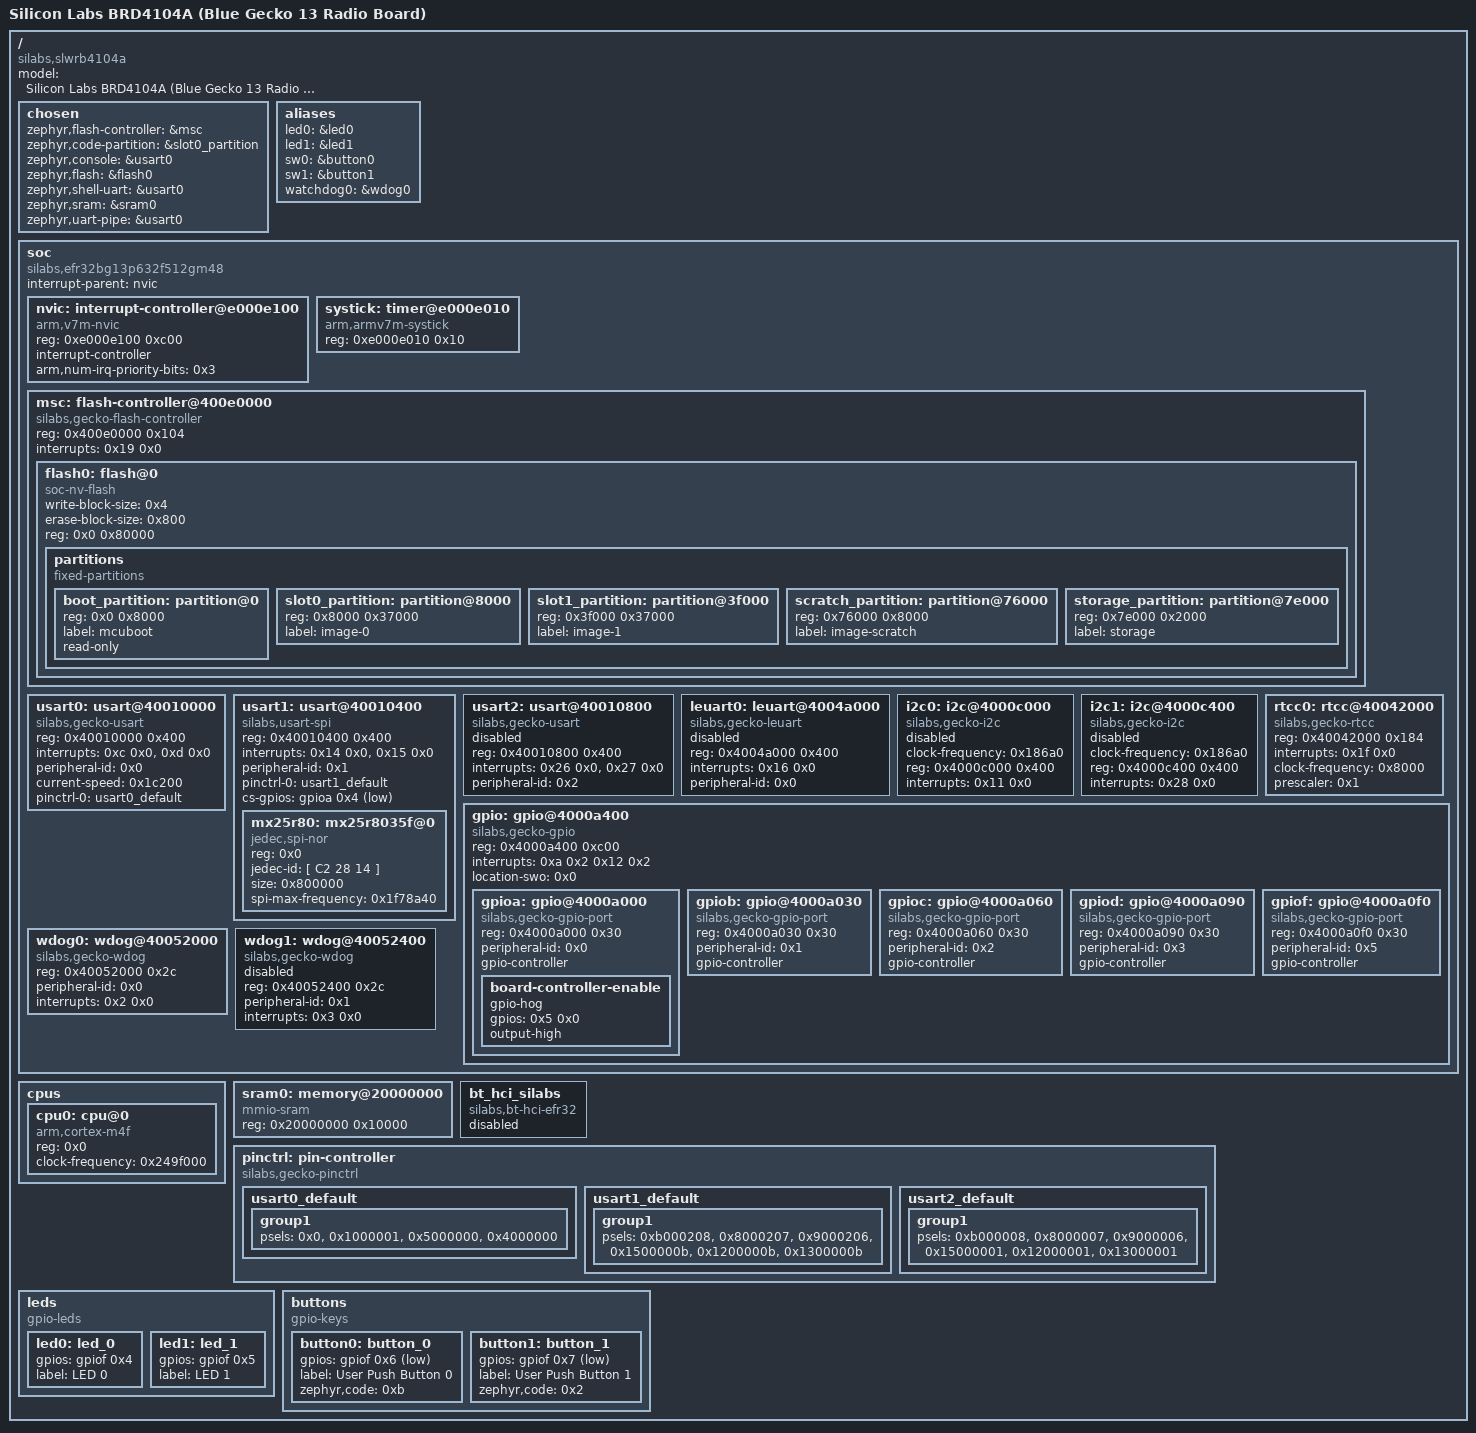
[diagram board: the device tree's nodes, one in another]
/dts-v1/;

/* node '/' defined in zephyr/dts/common/skeleton.dtsi:9 */
/ {
	#address-cells = < 0x1 >;                                    /* in zephyr/dts/common/skeleton.dtsi:10 */
	#size-cells = < 0x1 >;                                       /* in zephyr/dts/common/skeleton.dtsi:11 */
	model = "Silicon Labs BRD4104A (Blue Gecko 13 Radio Board)"; /* in zephyr/boards/silabs/radio_boards/slwrb4104a/slwrb4104a.dts:12 */
	compatible = "silabs,slwrb4104a",
	             "silabs,efr32bg13p";                            /* in zephyr/boards/silabs/radio_boards/slwrb4104a/slwrb4104a.dts:13 */

	/* node '/chosen' defined in zephyr/dts/common/skeleton.dtsi:13 */
	chosen {
		zephyr,flash-controller = &msc;           /* in zephyr/dts/arm/silabs/xg13/efr32xg13.dtsi:13 */
		zephyr,code-partition = &slot0_partition; /* in zephyr/boards/silabs/radio_boards/common/efr32-series1-common.dtsi:12 */
		zephyr,console = &usart0;                 /* in zephyr/boards/silabs/radio_boards/common/efr32-series1-common.dtsi:13 */
		zephyr,flash = &flash0;                   /* in zephyr/boards/silabs/radio_boards/common/efr32-series1-common.dtsi:14 */
		zephyr,shell-uart = &usart0;              /* in zephyr/boards/silabs/radio_boards/common/efr32-series1-common.dtsi:15 */
		zephyr,sram = &sram0;                     /* in zephyr/boards/silabs/radio_boards/common/efr32-series1-common.dtsi:16 */
		zephyr,uart-pipe = &usart0;               /* in zephyr/boards/silabs/radio_boards/common/efr32-series1-common.dtsi:17 */
	};

	/* node '/aliases' defined in zephyr/dts/common/skeleton.dtsi:15 */
	aliases {
		led0 = &led0;       /* in zephyr/boards/silabs/radio_boards/common/efr32-series1-common.dtsi:22 */
		led1 = &led1;       /* in zephyr/boards/silabs/radio_boards/common/efr32-series1-common.dtsi:23 */
		sw0 = &button0;     /* in zephyr/boards/silabs/radio_boards/common/efr32-series1-common.dtsi:24 */
		sw1 = &button1;     /* in zephyr/boards/silabs/radio_boards/common/efr32-series1-common.dtsi:25 */
		watchdog0 = &wdog0; /* in zephyr/boards/silabs/radio_boards/common/efr32-series1-common.dtsi:26 */
	};

	/* node '/soc' defined in zephyr/dts/arm/armv7-m.dtsi:6 */
	soc {
		#address-cells = < 0x1 >;                    /* in zephyr/dts/arm/armv7-m.dtsi:7 */
		#size-cells = < 0x1 >;                       /* in zephyr/dts/arm/armv7-m.dtsi:8 */
		interrupt-parent = < &nvic >;                /* in zephyr/dts/arm/armv7-m.dtsi:10 */
		ranges;                                      /* in zephyr/dts/arm/armv7-m.dtsi:11 */
		compatible = "silabs,efr32bg13p632f512gm48",
		             "silabs,efr32xg13p",
		             "silabs,efr32",
		             "simple-bus";                   /* in zephyr/dts/arm/silabs/xg13/efr32bg13p632f512gm48.dtsi:12 */

		/* node '/soc/interrupt-controller@e000e100' defined in zephyr/dts/arm/armv7-m.dtsi:13 */
		nvic: interrupt-controller@e000e100 {
			#address-cells = < 0x1 >;            /* in zephyr/dts/arm/armv7-m.dtsi:14 */
			compatible = "arm,v7m-nvic";         /* in zephyr/dts/arm/armv7-m.dtsi:15 */
			reg = < 0xe000e100 0xc00 >;          /* in zephyr/dts/arm/armv7-m.dtsi:16 */
			interrupt-controller;                /* in zephyr/dts/arm/armv7-m.dtsi:17 */
			#interrupt-cells = < 0x2 >;          /* in zephyr/dts/arm/armv7-m.dtsi:18 */
			arm,num-irq-priority-bits = < 0x3 >; /* in zephyr/dts/arm/silabs/xg13/efr32xg13.dtsi:198 */
			phandle = < 0x1 >;                   /* in zephyr/dts/arm/armv7-m.dtsi:10 */
		};

		/* node '/soc/timer@e000e010' defined in zephyr/dts/arm/armv7-m.dtsi:21 */
		systick: timer@e000e010 {
			compatible = "arm,armv7m-systick"; /* in zephyr/dts/arm/armv7-m.dtsi:22 */
			reg = < 0xe000e010 0x10 >;         /* in zephyr/dts/arm/armv7-m.dtsi:23 */
		};

		/* node '/soc/flash-controller@400e0000' defined in zephyr/dts/arm/silabs/xg13/efr32xg13.dtsi:31 */
		msc: flash-controller@400e0000 {
			compatible = "silabs,gecko-flash-controller"; /* in zephyr/dts/arm/silabs/xg13/efr32xg13.dtsi:32 */
			reg = < 0x400e0000 0x104 >;                   /* in zephyr/dts/arm/silabs/xg13/efr32xg13.dtsi:33 */
			interrupts = < 0x19 0x0 >;                    /* in zephyr/dts/arm/silabs/xg13/efr32xg13.dtsi:34 */
			#address-cells = < 0x1 >;                     /* in zephyr/dts/arm/silabs/xg13/efr32xg13.dtsi:36 */
			#size-cells = < 0x1 >;                        /* in zephyr/dts/arm/silabs/xg13/efr32xg13.dtsi:37 */

			/* node '/soc/flash-controller@400e0000/flash@0' defined in zephyr/dts/arm/silabs/xg13/efr32xg13.dtsi:39 */
			flash0: flash@0 {
				compatible = "soc-nv-flash";  /* in zephyr/dts/arm/silabs/xg13/efr32xg13.dtsi:40 */
				write-block-size = < 0x4 >;   /* in zephyr/dts/arm/silabs/xg13/efr32xg13.dtsi:41 */
				erase-block-size = < 0x800 >; /* in zephyr/dts/arm/silabs/xg13/efr32xg13.dtsi:42 */
				reg = < 0x0 0x80000 >;        /* in zephyr/dts/arm/silabs/xg13/efr32bg13p632f512gm48.dtsi:18 */

				/* node '/soc/flash-controller@400e0000/flash@0/partitions' defined in zephyr/boards/silabs/radio_boards/slwrb4104a/slwrb4104a.dts:21 */
				partitions {
					compatible = "fixed-partitions"; /* in zephyr/boards/silabs/radio_boards/slwrb4104a/slwrb4104a.dts:22 */
					#address-cells = < 0x1 >;        /* in zephyr/boards/silabs/radio_boards/slwrb4104a/slwrb4104a.dts:23 */
					#size-cells = < 0x1 >;           /* in zephyr/boards/silabs/radio_boards/slwrb4104a/slwrb4104a.dts:24 */

					/* node '/soc/flash-controller@400e0000/flash@0/partitions/partition@0' defined in zephyr/boards/silabs/radio_boards/slwrb4104a/slwrb4104a.dts:27 */
					boot_partition: partition@0 {
						reg = < 0x0 0x8000 >; /* in zephyr/boards/silabs/radio_boards/slwrb4104a/slwrb4104a.dts:28 */
						label = "mcuboot";    /* in zephyr/boards/silabs/radio_boards/slwrb4104a/slwrb4104a.dts:29 */
						read-only;            /* in zephyr/boards/silabs/radio_boards/slwrb4104a/slwrb4104a.dts:30 */
					};

					/* node '/soc/flash-controller@400e0000/flash@0/partitions/partition@8000' defined in zephyr/boards/silabs/radio_boards/slwrb4104a/slwrb4104a.dts:34 */
					slot0_partition: partition@8000 {
						reg = < 0x8000 0x37000 >; /* in zephyr/boards/silabs/radio_boards/slwrb4104a/slwrb4104a.dts:35 */
						label = "image-0";        /* in zephyr/boards/silabs/radio_boards/slwrb4104a/slwrb4104a.dts:36 */
					};

					/* node '/soc/flash-controller@400e0000/flash@0/partitions/partition@3f000' defined in zephyr/boards/silabs/radio_boards/slwrb4104a/slwrb4104a.dts:40 */
					slot1_partition: partition@3f000 {
						reg = < 0x3f000 0x37000 >; /* in zephyr/boards/silabs/radio_boards/slwrb4104a/slwrb4104a.dts:41 */
						label = "image-1";         /* in zephyr/boards/silabs/radio_boards/slwrb4104a/slwrb4104a.dts:42 */
					};

					/* node '/soc/flash-controller@400e0000/flash@0/partitions/partition@76000' defined in zephyr/boards/silabs/radio_boards/slwrb4104a/slwrb4104a.dts:46 */
					scratch_partition: partition@76000 {
						reg = < 0x76000 0x8000 >; /* in zephyr/boards/silabs/radio_boards/slwrb4104a/slwrb4104a.dts:47 */
						label = "image-scratch";  /* in zephyr/boards/silabs/radio_boards/slwrb4104a/slwrb4104a.dts:48 */
					};

					/* node '/soc/flash-controller@400e0000/flash@0/partitions/partition@7e000' defined in zephyr/boards/silabs/radio_boards/slwrb4104a/slwrb4104a.dts:52 */
					storage_partition: partition@7e000 {
						reg = < 0x7e000 0x2000 >; /* in zephyr/boards/silabs/radio_boards/slwrb4104a/slwrb4104a.dts:53 */
						label = "storage";        /* in zephyr/boards/silabs/radio_boards/slwrb4104a/slwrb4104a.dts:54 */
					};
				};
			};
		};

		/* node '/soc/usart@40010000' defined in zephyr/dts/arm/silabs/xg13/efr32xg13.dtsi:46 */
		usart0: usart@40010000 {
			compatible = "silabs,gecko-usart"; /* in zephyr/dts/arm/silabs/xg13/efr32xg13.dtsi:47 */
			reg = < 0x40010000 0x400 >;        /* in zephyr/dts/arm/silabs/xg13/efr32xg13.dtsi:48 */
			interrupts = < 0xc 0x0 >,
			             < 0xd 0x0 >;          /* in zephyr/dts/arm/silabs/xg13/efr32xg13.dtsi:49 */
			interrupt-names = "rx",
			                  "tx";            /* in zephyr/dts/arm/silabs/xg13/efr32xg13.dtsi:50 */
			peripheral-id = < 0x0 >;           /* in zephyr/dts/arm/silabs/xg13/efr32xg13.dtsi:51 */
			current-speed = < 0x1c200 >;       /* in zephyr/boards/silabs/radio_boards/common/efr32-series1-common.dtsi:63 */
			pinctrl-0 = < &usart0_default >;   /* in zephyr/boards/silabs/radio_boards/common/efr32-series1-common.dtsi:64 */
			pinctrl-names = "default";         /* in zephyr/boards/silabs/radio_boards/common/efr32-series1-common.dtsi:65 */
			status = "okay";                   /* in zephyr/boards/silabs/radio_boards/common/efr32-series1-common.dtsi:66 */
		};

		/* node '/soc/usart@40010400' defined in zephyr/dts/arm/silabs/xg13/efr32xg13.dtsi:55 */
		usart1: usart@40010400 {
			reg = < 0x40010400 0x400 >;      /* in zephyr/dts/arm/silabs/xg13/efr32xg13.dtsi:57 */
			interrupts = < 0x14 0x0 >,
			             < 0x15 0x0 >;       /* in zephyr/dts/arm/silabs/xg13/efr32xg13.dtsi:58 */
			interrupt-names = "rx",
			                  "tx";          /* in zephyr/dts/arm/silabs/xg13/efr32xg13.dtsi:59 */
			peripheral-id = < 0x1 >;         /* in zephyr/dts/arm/silabs/xg13/efr32xg13.dtsi:60 */
			compatible = "silabs,usart-spi"; /* in zephyr/boards/silabs/radio_boards/common/efr32-series1-common.dtsi:70 */
			#address-cells = < 0x1 >;        /* in zephyr/boards/silabs/radio_boards/common/efr32-series1-common.dtsi:72 */
			#size-cells = < 0x0 >;           /* in zephyr/boards/silabs/radio_boards/common/efr32-series1-common.dtsi:73 */
			pinctrl-0 = < &usart1_default >; /* in zephyr/boards/silabs/radio_boards/common/efr32-series1-common.dtsi:75 */
			pinctrl-names = "default";       /* in zephyr/boards/silabs/radio_boards/common/efr32-series1-common.dtsi:76 */
			cs-gpios = < &gpioa 0x4 0x1 >;   /* in zephyr/boards/silabs/radio_boards/common/efr32-series1-common.dtsi:78 */
			status = "okay";                 /* in zephyr/boards/silabs/radio_boards/common/efr32-series1-common.dtsi:80 */

			/* node '/soc/usart@40010400/mx25r8035f@0' defined in zephyr/boards/silabs/radio_boards/common/efr32-series1-common.dtsi:82 */
			mx25r80: mx25r8035f@0 {
				compatible = "jedec,spi-nor";      /* in zephyr/boards/silabs/radio_boards/common/efr32-series1-common.dtsi:83 */
				reg = < 0x0 >;                     /* in zephyr/boards/silabs/radio_boards/common/efr32-series1-common.dtsi:84 */
				jedec-id = [ C2 28 14 ];           /* in zephyr/boards/silabs/radio_boards/common/efr32-series1-common.dtsi:85 */
				size = < 0x800000 >;               /* in zephyr/boards/silabs/radio_boards/common/efr32-series1-common.dtsi:86 */
				spi-max-frequency = < 0x1f78a40 >; /* in zephyr/boards/silabs/radio_boards/common/efr32-series1-common.dtsi:87 */
			};
		};

		/* node '/soc/usart@40010800' defined in zephyr/dts/arm/silabs/xg13/efr32xg13.dtsi:64 */
		usart2: usart@40010800 {
			compatible = "silabs,gecko-usart"; /* in zephyr/dts/arm/silabs/xg13/efr32xg13.dtsi:65 */
			reg = < 0x40010800 0x400 >;        /* in zephyr/dts/arm/silabs/xg13/efr32xg13.dtsi:66 */
			interrupts = < 0x26 0x0 >,
			             < 0x27 0x0 >;         /* in zephyr/dts/arm/silabs/xg13/efr32xg13.dtsi:67 */
			interrupt-names = "rx",
			                  "tx";            /* in zephyr/dts/arm/silabs/xg13/efr32xg13.dtsi:68 */
			peripheral-id = < 0x2 >;           /* in zephyr/dts/arm/silabs/xg13/efr32xg13.dtsi:69 */
			status = "disabled";               /* in zephyr/dts/arm/silabs/xg13/efr32xg13.dtsi:70 */
		};

		/* node '/soc/leuart@4004a000' defined in zephyr/dts/arm/silabs/xg13/efr32xg13.dtsi:73 */
		leuart0: leuart@4004a000 {
			compatible = "silabs,gecko-leuart"; /* in zephyr/dts/arm/silabs/xg13/efr32xg13.dtsi:74 */
			reg = < 0x4004a000 0x400 >;         /* in zephyr/dts/arm/silabs/xg13/efr32xg13.dtsi:75 */
			interrupts = < 0x16 0x0 >;          /* in zephyr/dts/arm/silabs/xg13/efr32xg13.dtsi:76 */
			peripheral-id = < 0x0 >;            /* in zephyr/dts/arm/silabs/xg13/efr32xg13.dtsi:77 */
			status = "disabled";                /* in zephyr/dts/arm/silabs/xg13/efr32xg13.dtsi:78 */
		};

		/* node '/soc/i2c@4000c000' defined in zephyr/dts/arm/silabs/xg13/efr32xg13.dtsi:81 */
		i2c0: i2c@4000c000 {
			compatible = "silabs,gecko-i2c"; /* in zephyr/dts/arm/silabs/xg13/efr32xg13.dtsi:82 */
			clock-frequency = < 0x186a0 >;   /* in zephyr/dts/arm/silabs/xg13/efr32xg13.dtsi:83 */
			#address-cells = < 0x1 >;        /* in zephyr/dts/arm/silabs/xg13/efr32xg13.dtsi:84 */
			#size-cells = < 0x0 >;           /* in zephyr/dts/arm/silabs/xg13/efr32xg13.dtsi:85 */
			reg = < 0x4000c000 0x400 >;      /* in zephyr/dts/arm/silabs/xg13/efr32xg13.dtsi:86 */
			interrupts = < 0x11 0x0 >;       /* in zephyr/dts/arm/silabs/xg13/efr32xg13.dtsi:87 */
			status = "disabled";             /* in zephyr/dts/arm/silabs/xg13/efr32xg13.dtsi:88 */
		};

		/* node '/soc/i2c@4000c400' defined in zephyr/dts/arm/silabs/xg13/efr32xg13.dtsi:91 */
		i2c1: i2c@4000c400 {
			compatible = "silabs,gecko-i2c"; /* in zephyr/dts/arm/silabs/xg13/efr32xg13.dtsi:92 */
			clock-frequency = < 0x186a0 >;   /* in zephyr/dts/arm/silabs/xg13/efr32xg13.dtsi:93 */
			#address-cells = < 0x1 >;        /* in zephyr/dts/arm/silabs/xg13/efr32xg13.dtsi:94 */
			#size-cells = < 0x0 >;           /* in zephyr/dts/arm/silabs/xg13/efr32xg13.dtsi:95 */
			reg = < 0x4000c400 0x400 >;      /* in zephyr/dts/arm/silabs/xg13/efr32xg13.dtsi:96 */
			interrupts = < 0x28 0x0 >;       /* in zephyr/dts/arm/silabs/xg13/efr32xg13.dtsi:97 */
			status = "disabled";             /* in zephyr/dts/arm/silabs/xg13/efr32xg13.dtsi:98 */
		};

		/* node '/soc/rtcc@40042000' defined in zephyr/dts/arm/silabs/xg13/efr32xg13.dtsi:101 */
		rtcc0: rtcc@40042000 {
			compatible = "silabs,gecko-rtcc"; /* in zephyr/dts/arm/silabs/xg13/efr32xg13.dtsi:102 */
			reg = < 0x40042000 0x184 >;       /* in zephyr/dts/arm/silabs/xg13/efr32xg13.dtsi:103 */
			interrupts = < 0x1f 0x0 >;        /* in zephyr/dts/arm/silabs/xg13/efr32xg13.dtsi:104 */
			clock-frequency = < 0x8000 >;     /* in zephyr/dts/arm/silabs/xg13/efr32xg13.dtsi:105 */
			prescaler = < 0x1 >;              /* in zephyr/boards/silabs/radio_boards/common/efr32-series1-common.dtsi:92 */
			status = "okay";                  /* in zephyr/boards/silabs/radio_boards/common/efr32-series1-common.dtsi:93 */
		};

		/* node '/soc/gpio@4000a400' defined in zephyr/dts/arm/silabs/xg13/efr32xg13.dtsi:110 */
		gpio: gpio@4000a400 {
			compatible = "silabs,gecko-gpio";  /* in zephyr/dts/arm/silabs/xg13/efr32xg13.dtsi:111 */
			reg = < 0x4000a400 0xc00 >;        /* in zephyr/dts/arm/silabs/xg13/efr32xg13.dtsi:112 */
			interrupts = < 0xa 0x2 0x12 0x2 >; /* in zephyr/dts/arm/silabs/xg13/efr32xg13.dtsi:113 */
			interrupt-names = "GPIO_EVEN",
			                  "GPIO_ODD";      /* in zephyr/dts/arm/silabs/xg13/efr32xg13.dtsi:114 */
			ranges;                            /* in zephyr/dts/arm/silabs/xg13/efr32xg13.dtsi:116 */
			#address-cells = < 0x1 >;          /* in zephyr/dts/arm/silabs/xg13/efr32xg13.dtsi:117 */
			#size-cells = < 0x1 >;             /* in zephyr/dts/arm/silabs/xg13/efr32xg13.dtsi:118 */
			location-swo = < 0x0 >;            /* in zephyr/boards/silabs/radio_boards/common/efr32-series1-common.dtsi:97 */
			status = "okay";                   /* in zephyr/boards/silabs/radio_boards/common/efr32-series1-common.dtsi:98 */

			/* node '/soc/gpio@4000a400/gpio@4000a000' defined in zephyr/dts/arm/silabs/xg13/efr32xg13.dtsi:120 */
			gpioa: gpio@4000a000 {
				compatible = "silabs,gecko-gpio-port"; /* in zephyr/dts/arm/silabs/xg13/efr32xg13.dtsi:121 */
				reg = < 0x4000a000 0x30 >;             /* in zephyr/dts/arm/silabs/xg13/efr32xg13.dtsi:122 */
				peripheral-id = < 0x0 >;               /* in zephyr/dts/arm/silabs/xg13/efr32xg13.dtsi:123 */
				gpio-controller;                       /* in zephyr/dts/arm/silabs/xg13/efr32xg13.dtsi:124 */
				#gpio-cells = < 0x2 >;                 /* in zephyr/dts/arm/silabs/xg13/efr32xg13.dtsi:125 */
				status = "okay";                       /* in zephyr/boards/silabs/radio_boards/common/efr32-series1-common.dtsi:102 */
				phandle = < 0x4 >;                     /* in zephyr/boards/silabs/radio_boards/common/efr32-series1-common.dtsi:78 */

				/* node '/soc/gpio@4000a400/gpio@4000a000/board-controller-enable' defined in zephyr/boards/silabs/radio_boards/common/efr32-series1-common.dtsi:104 */
				board-controller-enable {
					gpio-hog;            /* in zephyr/boards/silabs/radio_boards/common/efr32-series1-common.dtsi:105 */
					gpios = < 0x5 0x0 >; /* in zephyr/boards/silabs/radio_boards/common/efr32-series1-common.dtsi:106 */
					output-high;         /* in zephyr/boards/silabs/radio_boards/common/efr32-series1-common.dtsi:107 */
				};
			};

			/* node '/soc/gpio@4000a400/gpio@4000a030' defined in zephyr/dts/arm/silabs/xg13/efr32xg13.dtsi:129 */
			gpiob: gpio@4000a030 {
				compatible = "silabs,gecko-gpio-port"; /* in zephyr/dts/arm/silabs/xg13/efr32xg13.dtsi:130 */
				reg = < 0x4000a030 0x30 >;             /* in zephyr/dts/arm/silabs/xg13/efr32xg13.dtsi:131 */
				peripheral-id = < 0x1 >;               /* in zephyr/dts/arm/silabs/xg13/efr32xg13.dtsi:132 */
				gpio-controller;                       /* in zephyr/dts/arm/silabs/xg13/efr32xg13.dtsi:133 */
				#gpio-cells = < 0x2 >;                 /* in zephyr/dts/arm/silabs/xg13/efr32xg13.dtsi:134 */
				status = "okay";                       /* in zephyr/boards/silabs/radio_boards/common/efr32-series1-common.dtsi:112 */
			};

			/* node '/soc/gpio@4000a400/gpio@4000a060' defined in zephyr/dts/arm/silabs/xg13/efr32xg13.dtsi:138 */
			gpioc: gpio@4000a060 {
				compatible = "silabs,gecko-gpio-port"; /* in zephyr/dts/arm/silabs/xg13/efr32xg13.dtsi:139 */
				reg = < 0x4000a060 0x30 >;             /* in zephyr/dts/arm/silabs/xg13/efr32xg13.dtsi:140 */
				peripheral-id = < 0x2 >;               /* in zephyr/dts/arm/silabs/xg13/efr32xg13.dtsi:141 */
				gpio-controller;                       /* in zephyr/dts/arm/silabs/xg13/efr32xg13.dtsi:142 */
				#gpio-cells = < 0x2 >;                 /* in zephyr/dts/arm/silabs/xg13/efr32xg13.dtsi:143 */
				status = "okay";                       /* in zephyr/boards/silabs/radio_boards/common/efr32-series1-common.dtsi:116 */
			};

			/* node '/soc/gpio@4000a400/gpio@4000a090' defined in zephyr/dts/arm/silabs/xg13/efr32xg13.dtsi:147 */
			gpiod: gpio@4000a090 {
				compatible = "silabs,gecko-gpio-port"; /* in zephyr/dts/arm/silabs/xg13/efr32xg13.dtsi:148 */
				reg = < 0x4000a090 0x30 >;             /* in zephyr/dts/arm/silabs/xg13/efr32xg13.dtsi:149 */
				peripheral-id = < 0x3 >;               /* in zephyr/dts/arm/silabs/xg13/efr32xg13.dtsi:150 */
				gpio-controller;                       /* in zephyr/dts/arm/silabs/xg13/efr32xg13.dtsi:151 */
				#gpio-cells = < 0x2 >;                 /* in zephyr/dts/arm/silabs/xg13/efr32xg13.dtsi:152 */
				status = "okay";                       /* in zephyr/boards/silabs/radio_boards/common/efr32-series1-common.dtsi:120 */
			};

			/* node '/soc/gpio@4000a400/gpio@4000a0f0' defined in zephyr/dts/arm/silabs/xg13/efr32xg13.dtsi:156 */
			gpiof: gpio@4000a0f0 {
				compatible = "silabs,gecko-gpio-port"; /* in zephyr/dts/arm/silabs/xg13/efr32xg13.dtsi:157 */
				reg = < 0x4000a0f0 0x30 >;             /* in zephyr/dts/arm/silabs/xg13/efr32xg13.dtsi:158 */
				peripheral-id = < 0x5 >;               /* in zephyr/dts/arm/silabs/xg13/efr32xg13.dtsi:159 */
				gpio-controller;                       /* in zephyr/dts/arm/silabs/xg13/efr32xg13.dtsi:160 */
				#gpio-cells = < 0x2 >;                 /* in zephyr/dts/arm/silabs/xg13/efr32xg13.dtsi:161 */
				status = "okay";                       /* in zephyr/boards/silabs/radio_boards/common/efr32-series1-common.dtsi:124 */
				phandle = < 0x5 >;                     /* in zephyr/boards/silabs/radio_boards/common/efr32-series1-common.dtsi:33 */
			};
		};

		/* node '/soc/wdog@40052000' defined in zephyr/dts/arm/silabs/xg13/efr32xg13.dtsi:166 */
		wdog0: wdog@40052000 {
			compatible = "silabs,gecko-wdog"; /* in zephyr/dts/arm/silabs/xg13/efr32xg13.dtsi:167 */
			reg = < 0x40052000 0x2c >;        /* in zephyr/dts/arm/silabs/xg13/efr32xg13.dtsi:168 */
			peripheral-id = < 0x0 >;          /* in zephyr/dts/arm/silabs/xg13/efr32xg13.dtsi:169 */
			interrupts = < 0x2 0x0 >;         /* in zephyr/dts/arm/silabs/xg13/efr32xg13.dtsi:170 */
			status = "okay";                  /* in zephyr/boards/silabs/radio_boards/common/efr32-series1-common.dtsi:128 */
		};

		/* node '/soc/wdog@40052400' defined in zephyr/dts/arm/silabs/xg13/efr32xg13.dtsi:174 */
		wdog1: wdog@40052400 {
			compatible = "silabs,gecko-wdog"; /* in zephyr/dts/arm/silabs/xg13/efr32xg13.dtsi:175 */
			reg = < 0x40052400 0x2c >;        /* in zephyr/dts/arm/silabs/xg13/efr32xg13.dtsi:176 */
			peripheral-id = < 0x1 >;          /* in zephyr/dts/arm/silabs/xg13/efr32xg13.dtsi:177 */
			interrupts = < 0x3 0x0 >;         /* in zephyr/dts/arm/silabs/xg13/efr32xg13.dtsi:178 */
			status = "disabled";              /* in zephyr/dts/arm/silabs/xg13/efr32xg13.dtsi:179 */
		};
	};

	/* node '/cpus' defined in zephyr/dts/arm/silabs/xg13/efr32xg13.dtsi:16 */
	cpus {
		#address-cells = < 0x1 >; /* in zephyr/dts/arm/silabs/xg13/efr32xg13.dtsi:17 */
		#size-cells = < 0x0 >;    /* in zephyr/dts/arm/silabs/xg13/efr32xg13.dtsi:18 */

		/* node '/cpus/cpu@0' defined in zephyr/dts/arm/silabs/xg13/efr32xg13.dtsi:20 */
		cpu0: cpu@0 {
			compatible = "arm,cortex-m4f";   /* in zephyr/dts/arm/silabs/xg13/efr32xg13.dtsi:21 */
			reg = < 0x0 >;                   /* in zephyr/dts/arm/silabs/xg13/efr32xg13.dtsi:22 */
			clock-frequency = < 0x249f000 >; /* in zephyr/boards/silabs/radio_boards/slwrb4104a/slwrb4104a.dts:17 */
		};
	};

	/* node '/memory@20000000' defined in zephyr/dts/arm/silabs/xg13/efr32xg13.dtsi:26 */
	sram0: memory@20000000 {
		compatible = "mmio-sram";     /* in zephyr/dts/arm/silabs/xg13/efr32xg13.dtsi:27 */
		reg = < 0x20000000 0x10000 >; /* in zephyr/dts/arm/silabs/xg13/efr32bg13p632f512gm48.dtsi:22 */
	};

	/* node '/bt_hci_silabs' defined in zephyr/dts/arm/silabs/xg13/efr32xg13.dtsi:183 */
	bt_hci_silabs: bt_hci_silabs {
		compatible = "silabs,bt-hci-efr32"; /* in zephyr/dts/arm/silabs/xg13/efr32xg13.dtsi:184 */
		status = "disabled";                /* in zephyr/dts/arm/silabs/xg13/efr32xg13.dtsi:185 */
	};

	/* node '/pin-controller' defined in zephyr/dts/arm/silabs/xg13/efr32xg13.dtsi:188 */
	pinctrl: pin-controller {
		compatible = "silabs,gecko-pinctrl"; /* in zephyr/dts/arm/silabs/xg13/efr32xg13.dtsi:193 */

		/* node '/pin-controller/usart0_default' defined in zephyr/boards/silabs/radio_boards/common/efr32-series1-common-pinctrl.dtsi:11 */
		usart0_default: usart0_default {
			phandle = < 0x2 >; /* in zephyr/boards/silabs/radio_boards/common/efr32-series1-common.dtsi:64 */

			/* node '/pin-controller/usart0_default/group1' defined in zephyr/boards/silabs/radio_boards/common/efr32-series1-common-pinctrl.dtsi:12 */
			group1 {
				psels = < 0x0 >,
				        < 0x1000001 >,
				        < 0x5000000 >,
				        < 0x4000000 >; /* in zephyr/boards/silabs/radio_boards/common/efr32-series1-common-pinctrl.dtsi:13 */
			};
		};

		/* node '/pin-controller/usart1_default' defined in zephyr/boards/silabs/radio_boards/common/efr32-series1-common-pinctrl.dtsi:20 */
		usart1_default: usart1_default {
			phandle = < 0x3 >; /* in zephyr/boards/silabs/radio_boards/common/efr32-series1-common.dtsi:75 */

			/* node '/pin-controller/usart1_default/group1' defined in zephyr/boards/silabs/radio_boards/common/efr32-series1-common-pinctrl.dtsi:21 */
			group1 {
				psels = < 0xb000208 >,
				        < 0x8000207 >,
				        < 0x9000206 >,
				        < 0x1500000b >,
				        < 0x1200000b >,
				        < 0x1300000b >; /* in zephyr/boards/silabs/radio_boards/common/efr32-series1-common-pinctrl.dtsi:22 */
			};
		};

		/* node '/pin-controller/usart2_default' defined in zephyr/boards/silabs/radio_boards/common/efr32-series1-common-pinctrl.dtsi:31 */
		usart2_default: usart2_default {

			/* node '/pin-controller/usart2_default/group1' defined in zephyr/boards/silabs/radio_boards/common/efr32-series1-common-pinctrl.dtsi:32 */
			group1 {
				psels = < 0xb000008 >,
				        < 0x8000007 >,
				        < 0x9000006 >,
				        < 0x15000001 >,
				        < 0x12000001 >,
				        < 0x13000001 >; /* in zephyr/boards/silabs/radio_boards/common/efr32-series1-common-pinctrl.dtsi:33 */
			};
		};
	};

	/* node '/leds' defined in zephyr/boards/silabs/radio_boards/common/efr32-series1-common.dtsi:29 */
	leds {
		compatible = "gpio-leds"; /* in zephyr/boards/silabs/radio_boards/common/efr32-series1-common.dtsi:30 */

		/* node '/leds/led_0' defined in zephyr/boards/silabs/radio_boards/common/efr32-series1-common.dtsi:32 */
		led0: led_0 {
			gpios = < &gpiof 0x4 0x0 >; /* in zephyr/boards/silabs/radio_boards/common/efr32-series1-common.dtsi:33 */
			label = "LED 0";            /* in zephyr/boards/silabs/radio_boards/common/efr32-series1-common.dtsi:34 */
		};

		/* node '/leds/led_1' defined in zephyr/boards/silabs/radio_boards/common/efr32-series1-common.dtsi:37 */
		led1: led_1 {
			gpios = < &gpiof 0x5 0x0 >; /* in zephyr/boards/silabs/radio_boards/common/efr32-series1-common.dtsi:38 */
			label = "LED 1";            /* in zephyr/boards/silabs/radio_boards/common/efr32-series1-common.dtsi:39 */
		};
	};

	/* node '/buttons' defined in zephyr/boards/silabs/radio_boards/common/efr32-series1-common.dtsi:43 */
	buttons {
		compatible = "gpio-keys"; /* in zephyr/boards/silabs/radio_boards/common/efr32-series1-common.dtsi:44 */

		/* node '/buttons/button_0' defined in zephyr/boards/silabs/radio_boards/common/efr32-series1-common.dtsi:46 */
		button0: button_0 {
			gpios = < &gpiof 0x6 0x1 >;   /* in zephyr/boards/silabs/radio_boards/common/efr32-series1-common.dtsi:48 */
			label = "User Push Button 0"; /* in zephyr/boards/silabs/radio_boards/common/efr32-series1-common.dtsi:49 */
			zephyr,code = < 0xb >;        /* in zephyr/boards/silabs/radio_boards/common/efr32-series1-common.dtsi:50 */
		};

		/* node '/buttons/button_1' defined in zephyr/boards/silabs/radio_boards/common/efr32-series1-common.dtsi:53 */
		button1: button_1 {
			gpios = < &gpiof 0x7 0x1 >;   /* in zephyr/boards/silabs/radio_boards/common/efr32-series1-common.dtsi:55 */
			label = "User Push Button 1"; /* in zephyr/boards/silabs/radio_boards/common/efr32-series1-common.dtsi:56 */
			zephyr,code = < 0x2 >;        /* in zephyr/boards/silabs/radio_boards/common/efr32-series1-common.dtsi:57 */
		};
	};
};
